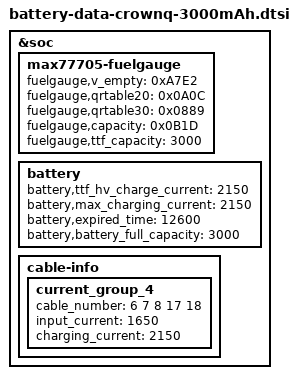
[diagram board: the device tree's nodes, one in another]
/*
 * SAMSUNG board device tree source
 *
 * Copyright (c) 2018 Samsung Electronics Co., Ltd.
 *		http://www.samsung.com
 *
 * This program is free software; you can redistribute it and/or modify
 * it under the terms of the GNU General Public License version 2 as
 * published by the Free Software Foundation.
 */

/* This dtsi is only for hw id 00, 01, 02, 04, 05 */
#include "battery-data-crownq-common.dtsi"

&soc {
	max77705-fuelgauge {
		/* for 3000mAh temporary battery */
		fuelgauge,v_empty = <0xA7E2>; /* Empty: 3350mV, Recover: 3920mV */
		fuelgauge,qrtable20 = <0x0A0C>;
		fuelgauge,qrtable30 = <0x0889>;
		fuelgauge,capacity = <0x0B1D>;
		fuelgauge,ttf_capacity = <3000>;				
	};

	battery {
		battery,ttf_hv_charge_current = <2150>;	
		battery,max_charging_current = <2150>;
		battery,expired_time = <12600>;
		battery,battery_full_capacity = <3000>;
	};

	cable-info {
		current_group_4 {
			cable_number = <6 7 8 17 18>;
			input_current = <1650>;
			charging_current = <2150>;
		};
	};
};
